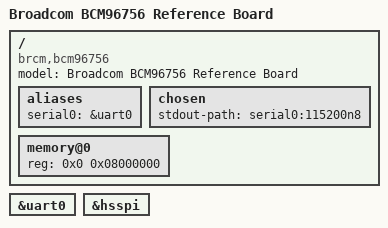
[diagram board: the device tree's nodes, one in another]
/dts-v1/;
#include "bcm6756.dtsi"
/ {
	model = "Broadcom BCM96756 Reference Board";
	compatible = "brcm,bcm96756", "brcm,bcm6756", "brcm,bcmbca";
	aliases {
		serial0 = &uart0;
	};
	chosen {
		stdout-path = "serial0:115200n8";
	};
	memory@0 {
		device_type = "memory";
		reg = <0x0 0x08000000>;
	};
};
&uart0 {
	status = "okay";
};
&hsspi {
	status = "okay";
};
